# R9A09G057H register map
Vendor: Renesas Electronics; File version: 1.0
Registers are 32-bit, read-write, no defined reset value unless marked. A register's access mark holds for its fields unless they carry their own. Offsets are from the block's base; [hi:lo] are bit positions; {n}, {i} and the like mark numbered series.

## R_ADC_E0 — IO define file for adc_e.
Base 0x11C00000
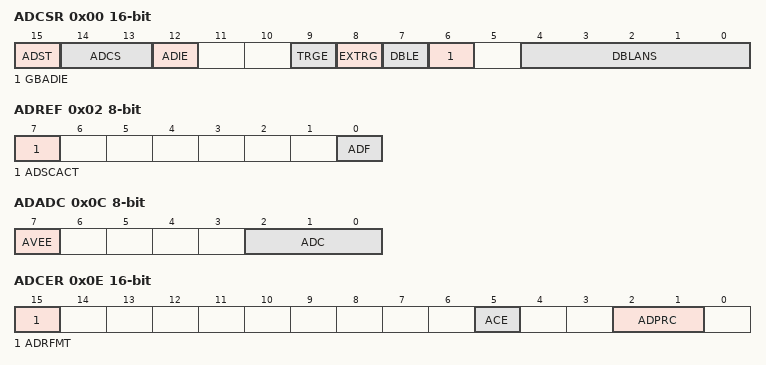
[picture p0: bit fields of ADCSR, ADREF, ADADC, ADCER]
0x00 ADCSR 16-bit
  [15] ADST, [14:13] ADCS, [12] ADIE, [9] TRGE, [8] EXTRG, [7] DBLE, [6] GBADIE, [4:0] DBLANS
0x02 ADREF 8-bit ro
  [7] ADSCACT, [0] ADF
0x04 ADANSA0 16-bit
  [7:0] ANSA0
0x08 ADADS0 16-bit
  [7:0] ADS0
0x0C ADADC 8-bit
  [7] AVEE, [2:0] ADC
0x0E ADCER 16-bit
  [15] ADRFMT, [5] ACE, [2:1] ADPRC
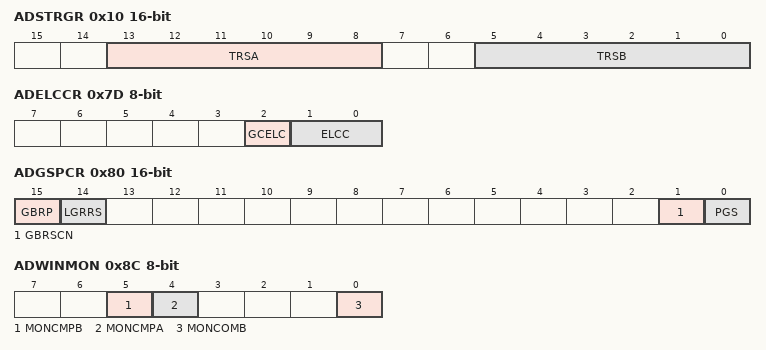
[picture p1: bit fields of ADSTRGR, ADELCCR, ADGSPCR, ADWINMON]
0x10 ADSTRGR 16-bit
  [13:8] TRSA, [5:0] TRSB
0x14 ADANSB0 16-bit
  [7:0] ANSB0
0x18 ADDBLDR 16-bit ro
  [15:0] DBLDR
{0x20+2i} ADDR{i} 16-bit ro (i=0..7)
  [15:0] DR
0x7D ADELCCR 8-bit
  [2] GCELC, [1:0] ELCC
0x80 ADGSPCR 16-bit
  [15] GBRP, [14] LGRRS, [1] GBRSCN, [0] PGS
0x84 ADDBLDRA 16-bit ro
  [15:0] DBLDRA
0x86 ADDBLDRB 16-bit ro
  [15:0] DBLDRB
0x8C ADWINMON 8-bit ro
  [5] MONCMPB, [4] MONCMPA, [0] MONCOMB
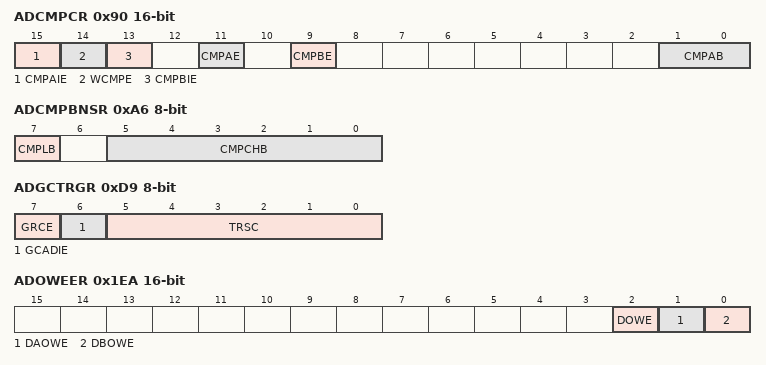
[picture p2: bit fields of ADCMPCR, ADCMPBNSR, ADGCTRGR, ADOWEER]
0x90 ADCMPCR 16-bit
  [15] CMPAIE, [14] WCMPE, [13] CMPBIE, [11] CMPAE, [9] CMPBE, [1:0] CMPAB
0x94 ADCMPANSR0 16-bit
  [7:0] CMPCHA0
0x98 ADCMPLR0 16-bit
  [7:0] CMPLCHA0
0x9C ADCMPDR0 16-bit
  [15:0] CMPLLA
0x9E ADCMPDR1 16-bit
  [15:0] CMPULA
0xA0 ADCMPSR0 16-bit
  [7:0] CMPSTCHA0
0xA6 ADCMPBNSR 8-bit
  [7] CMPLB, [5:0] CMPCHB
0xA8 ADWINLLB 16-bit
  [15:0] CMPLLB
0xAA ADWINULB 16-bit
  [15:0] CMPULB
0xAC ADCMPBSR 8-bit
  [0] CMPSTB
0xD4 ADANSC0 16-bit
  [7:0] ANSC0
0xD9 ADGCTRGR 8-bit
  [7] GRCE, [6] GCADIE, [5:0] TRSC
0x1E2 ADERCR 8-bit
  [2] OWEIE
0x1E3 ADERCLR 8-bit
  [2] OWEC
0x1E8 ADOWER 16-bit ro
  [7:0] OWE
0x1EA ADOWEER 16-bit ro
  [2] DOWE, [1] DAOWE, [0] DBOWE

## R_CMTW0 — IO define file for cmtw.
Base 0x11C01800
Same registers: R_CMTW1 0x11C01C00, R_CMTW2 0x11C02000, R_CMTW3 0x11C02400, R_CMTW4 0x13000C00, R_CMTW5 0x13001000, R_CMTW6 0x13001400, R_CMTW7 0x13001800
0x00 CMWSTR 16-bit
  [0] STR
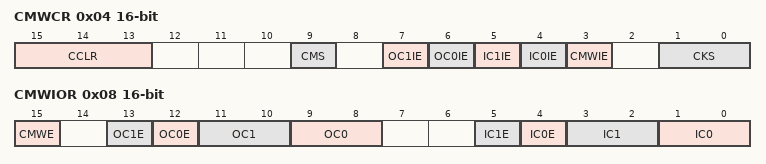
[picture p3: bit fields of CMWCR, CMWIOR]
0x04 CMWCR 16-bit
  [15:13] CCLR, [9] CMS, [7] OC1IE, [6] OC0IE, [5] IC1IE, [4] IC0IE, [3] CMWIE, [1:0] CKS
0x08 CMWIOR 16-bit
  [15] CMWE, [13] OC1E, [12] OC0E, [11:10] OC1, [9:8] OC0, [5] IC1E, [4] IC0E, [3:2] IC1, [1:0] IC0
0x10 CMWCNT
  [31:0] CNT
0x14 CMWCOR
  [31:0] COR
0x18 CMWICR0 ro
  [31:0] ICR
0x1C CMWICR1 ro
  [31:0] ICR
0x20 CMWOCR0
  [31:0] OCR
0x24 CMWOCR1
  [31:0] OCR

## R_GLOBAL_TIMER — IO define file for global_timer.
Base 0x12C10200
0x00 GTCR_L
0x04 GTCR_H
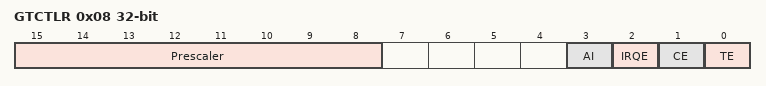
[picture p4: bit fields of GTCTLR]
0x08 GTCTLR
  [15:8] Prescaler, [3] AI, [2] IRQE, [1] CE, [0] TE
0x0C GTISR
  [0] EF
0x10 CVR_L
0x14 CVR_H
0x18 AUTO_INCR

## R_INTC_GIC — IO define file for intc_gic.
Base 0x12C10100
0x00 GICC_ICCICR
  [0] EN
0x04 GICC_ICCPMR
  [7:0] P
0x08 GICC_ICCBPR
  [2:0] BP
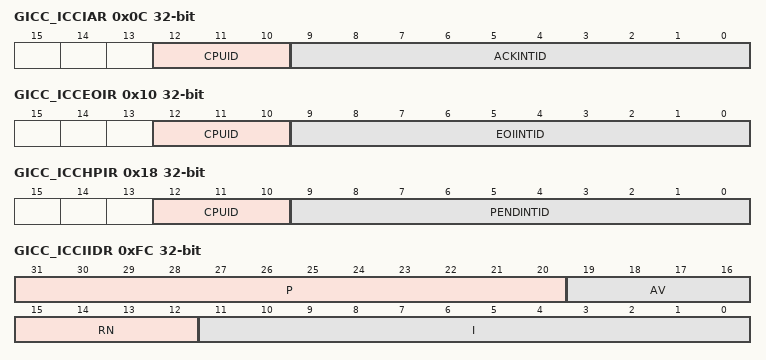
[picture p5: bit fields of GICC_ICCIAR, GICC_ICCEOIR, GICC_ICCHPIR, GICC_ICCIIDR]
0x0C GICC_ICCIAR ro
  [12:10] CPUID, [9:0] ACKINTID
0x10 GICC_ICCEOIR
  [12:10] CPUID wo, [9:0] EOIINTID wo
0x14 GICC_ICCRPR ro
  [7:0] P
0x18 GICC_ICCHPIR ro
  [12:10] CPUID, [9:0] PENDINTID
0xFC GICC_ICCIIDR ro
  [31:20] P, [19:16] AV, [15:12] RN, [11:0] I
0xF00 GICD_ICDDCR
  [0] EN
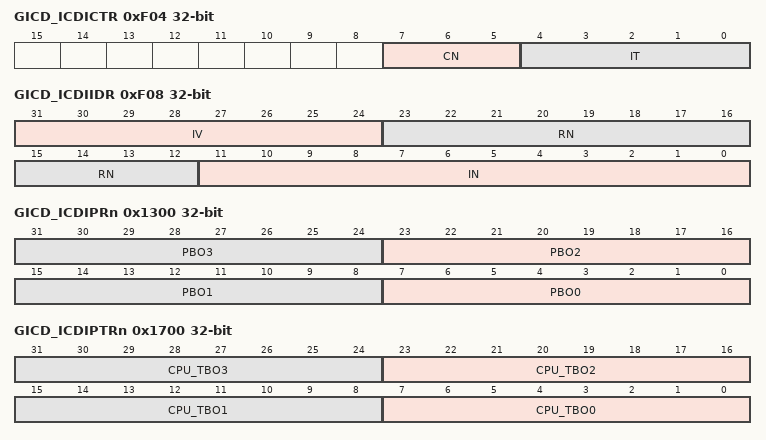
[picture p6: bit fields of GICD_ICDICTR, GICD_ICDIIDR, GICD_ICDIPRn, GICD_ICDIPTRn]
0xF04 GICD_ICDICTR ro
  [7:5] CN, [4:0] IT
0xF08 GICD_ICDIIDR ro
  [31:24] IV, [23:12] RN, [11:0] IN
0x1000 GICD_ICDISERn
  [31:0] SEB
0x1080 GICD_ICDICERn
  [31:0] CEB
0x1100 GICD_ICDISPRn
  [31:0] CPB
0x1180 GICD_ICDICPRn
  [31:0] CPB
0x1200 GICD_ICDABRn ro
  [31:0] AB
0x1300 GICD_ICDIPRn
  [8n+7:8n] PBO{n} (n=0..3)
0x1700 GICD_ICDIPTRn
  [8n+7:8n] CPU_TBO{n} (n=0..3)
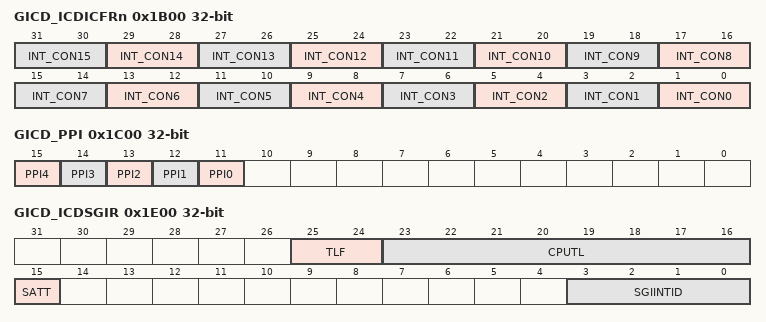
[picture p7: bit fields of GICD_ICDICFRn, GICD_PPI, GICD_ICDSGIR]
0x1B00 GICD_ICDICFRn
  [2n+1:2n] INT_CON{n} (n=0..15)
0x1C00 GICD_PPI
  [n+11] PPI{n} (n=0..4)
0x1C04 GICD_SPI ro
0x1E00 GICD_ICDSGIR
  [25:24] TLF, [23:16] CPUTL, [15] SATT, [3:0] SGIINTID
0x1ED0 GICD_PIR4 8-bit ro
  [7:0] ID
{0x1EE0+4i} GICD_PIR{i} 8-bit ro (i=0..3)
  [7:0] ID
{0x1EF0+4i} GICD_CIR{i} 8-bit ro (i=0..3)
  [7:0] ID

## R_PRIVATE_TIMER — IO define file for private_timer.
Base 0x12C10600
0x00 PTLR
0x04 PTCR
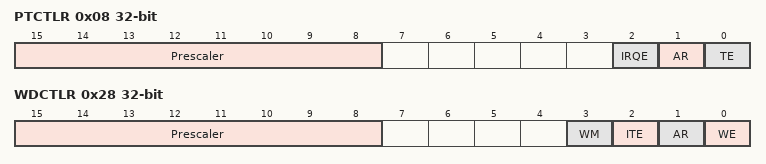
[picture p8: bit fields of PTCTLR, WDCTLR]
0x08 PTCTLR
  [15:8] Prescaler, [2] IRQE, [1] AR, [0] TE
0x0C PTISR
  [0] FLAG ro
0x0C PTISR_CLR
  [0] CLR wo
0x20 WDWLR
0x24 WDWCR
0x28 WDCTLR
  [15:8] Prescaler, [3] WM, [2] ITE, [1] AR, [0] WE
0x2C WDISR
  [0] FLAG ro
0x2C WDISR_CLR
  [0] CLR wo
0x30 WDRSR
  [0] RESET
0x34 WDDR wo
